# nvic register map
Vendor: Texas Instruments
Peripheral module from a debugger description file (folder MSP432).
Registers are 32-bit, read-write, no defined reset value unless marked. A register's access mark holds for its fields unless they carry their own. Offsets are as the file gives them; lines under a group give offsets from that group; [hi:lo] are bit positions; {n}, {i} and the like mark numbered series; 'fields as' and 'values as' point back to an identical list; <NAME> marks a mode.

## NVIC
0x100 ISER0 — Irq 0 to 31 Set Enable Register
  [31:0] SETENA — Writing 0 to a SETENA bit has no effect, writing 1 to a bit ena
0x104 ISER1 — Irq 32 to 63 Set Enable Register
  fields as ISER0
0x180 ICER0 — Irq 0 to 31 Clear Enable Register
  [31:0] CLRENA — Writing 0 to a CLRENA bit has no effect, writing 1 to a bit dis
0x184 ICER1 — Irq 32 to 63 Clear Enable Register
  fields as ICER0
0x200 ISPR0 — Irq 0 to 31 Set Pending Register
  [31:0] SETPEND — Writing 0 to a SETPEND bit has no effect, writing 1 to a bit pe
0x204 ISPR1 — Irq 32 to 63 Set Pending Register
  fields as ISPR0
0x280 ICPR0 — Irq 0 to 31 Clear Pending Register
  [31:0] CLRPEND — Writing 0 to a CLRPEND bit has no effect, writing 1 to a bit cl
0x284 ICPR1 — Irq 32 to 63 Clear Pending Register
  fields as ICPR0
0x300 IABR0 — Irq 0 to 31 Active Bit Register
  [31:0] ACTIVE — Interrupt active flags
0x304 IABR1 — Irq 32 to 63 Active Bit Register
  [31:0] ACTIVE — Interrupt active flags
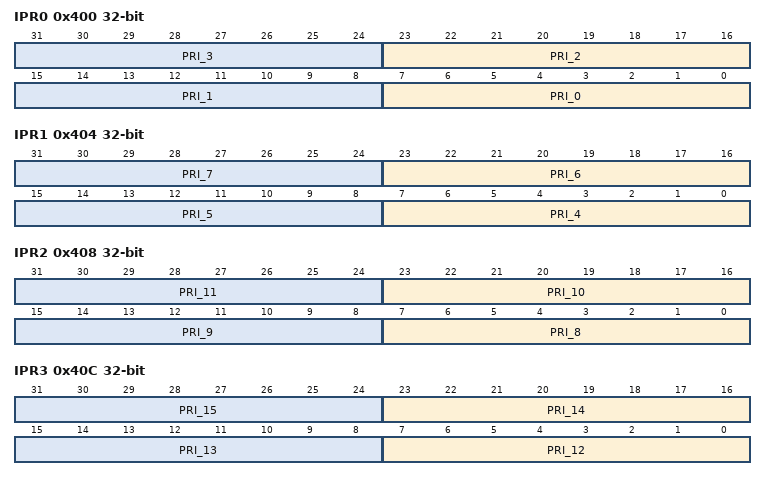
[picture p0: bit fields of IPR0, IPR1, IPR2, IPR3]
0x400 IPR0 — Irq 0 to 3 Priority Register
  [8n+7:8n] PRI_{n} (n=0..3) — Priority of interrupt {n}
0x404 IPR1 — Irq 4 to 7 Priority Register
  [8n-25:8n-32] PRI_{n} (n=4..7) — Priority of interrupt {n}
0x408 IPR2 — Irq 8 to 11 Priority Register
  [8n-57:8n-64] PRI_{n} (n=8..11) — Priority of interrupt {n}
0x40C IPR3 — Irq 12 to 15 Priority Register
  [8n-89:8n-96] PRI_{n} (n=12..15) — Priority of interrupt {n}
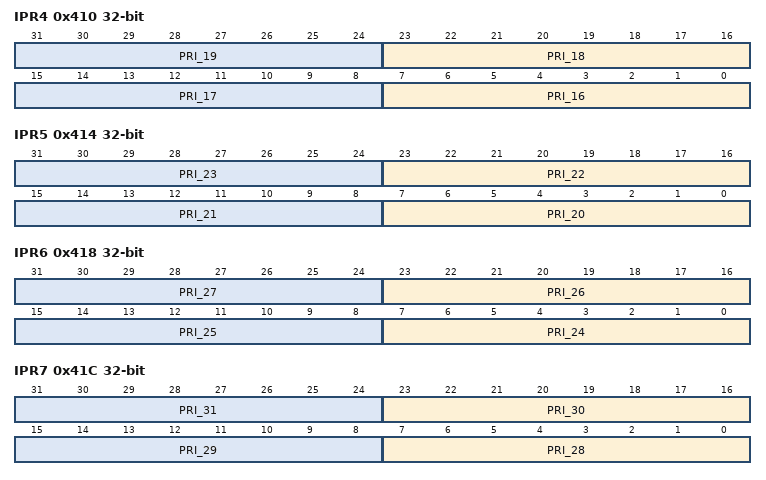
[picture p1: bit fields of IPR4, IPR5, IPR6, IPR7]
0x410 IPR4 — Irq 16 to 19 Priority Register
  [8n-121:8n-128] PRI_{n} (n=16..19) — Priority of interrupt {n}
0x414 IPR5 — Irq 20 to 23 Priority Register
  [8n-153:8n-160] PRI_{n} (n=20..23) — Priority of interrupt {n}
0x418 IPR6 — Irq 24 to 27 Priority Register
  [8n-185:8n-192] PRI_{n} (n=24..27) — Priority of interrupt {n}
0x41C IPR7 — Irq 28 to 31 Priority Register
  [8n-217:8n-224] PRI_{n} (n=28..31) — Priority of interrupt {n}
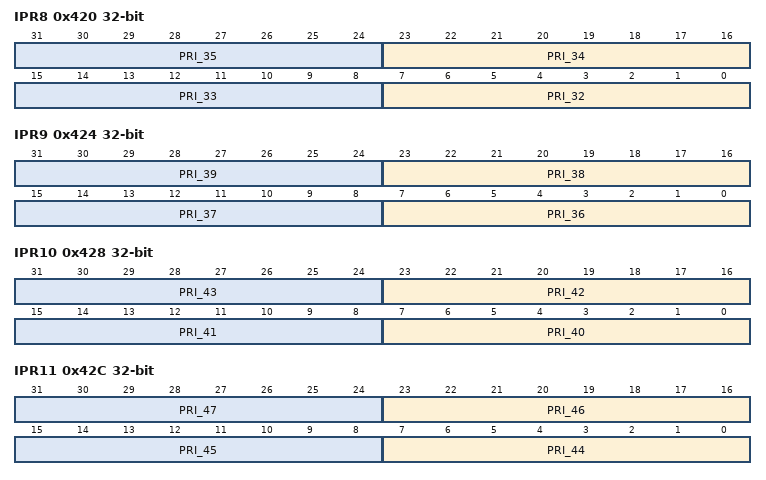
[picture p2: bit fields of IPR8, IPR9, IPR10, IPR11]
0x420 IPR8 — Irq 32 to 35 Priority Register
  [8n-249:8n-256] PRI_{n} (n=32..35) — Priority of interrupt {n}
0x424 IPR9 — Irq 36 to 39 Priority Register
  [8n-281:8n-288] PRI_{n} (n=36..39) — Priority of interrupt {n}
0x428 IPR10 — Irq 40 to 43 Priority Register
  [8n-313:8n-320] PRI_{n} (n=40..43) — Priority of interrupt {n}
0x42C IPR11 — Irq 44 to 47 Priority Register
  [8n-345:8n-352] PRI_{n} (n=44..47) — Priority of interrupt {n}
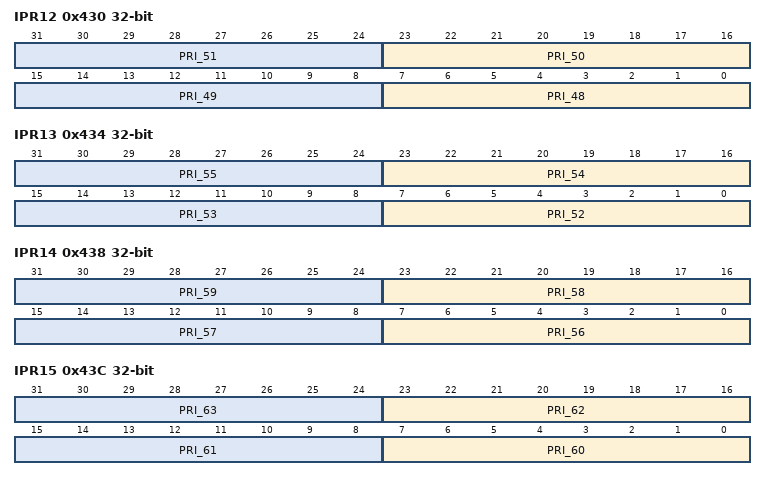
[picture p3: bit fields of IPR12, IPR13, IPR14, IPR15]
0x430 IPR12 — Irq 48 to 51 Priority Register
  [8n-377:8n-384] PRI_{n} (n=48..51) — Priority of interrupt {n}
0x434 IPR13 — Irq 52 to 55 Priority Register
  [8n-409:8n-416] PRI_{n} (n=52..55) — Priority of interrupt {n}
0x438 IPR14 — Irq 56 to 59 Priority Register
  [8n-441:8n-448] PRI_{n} (n=56..59) — Priority of interrupt {n}
0x43C IPR15 — Irq 60 to 63 Priority Register
  [8n-473:8n-480] PRI_{n} (n=60..63) — Priority of interrupt {n}
